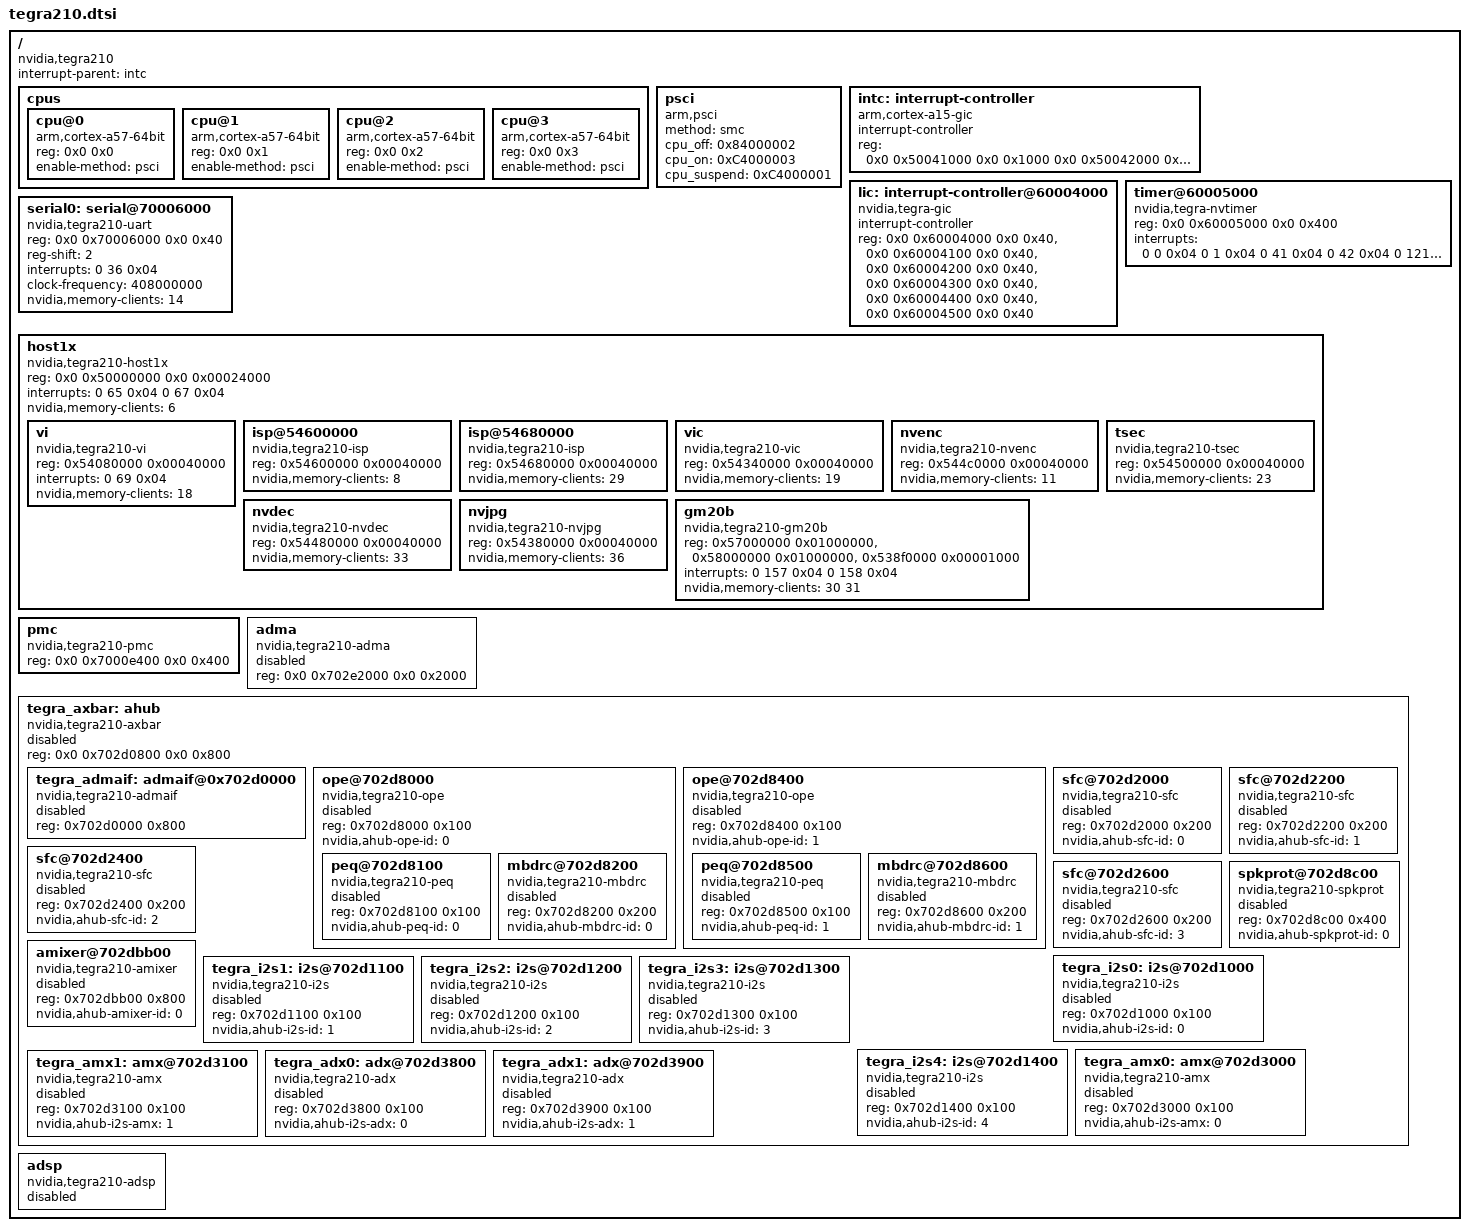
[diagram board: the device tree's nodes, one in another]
/*
 * arch/arm64/boot/dts/tegra210.dtsi
 *
 * Copyright (c) 2013-2014, NVIDIA CORPORATION.  All rights reserved.
 *
 * This program is free software; you can redistribute it and/or modify
 * it under the terms of the GNU General Public License as published by
 * the Free Software Foundation; version 2 of the License.
 *
 * This program is distributed in the hope that it will be useful, but WITHOUT
 * ANY WARRANTY; without even the implied warranty of MERCHANTABILITY or
 * FITNESS FOR A PARTICULAR PURPOSE.  See the GNU General Public License for
 * more details.
 *
 * You should have received a copy of the GNU General Public License along
 * with this program; if not, write to the Free Software Foundation, Inc.,
 * 51 Franklin Street, Fifth Floor, Boston, MA  02110-1301, USA.
 *
 */

/include/ "skeleton.dtsi"

/ {
	compatible = "nvidia,tegra210";
	interrupt-parent = <&intc>;
	#address-cells = <2>;
	#size-cells = <2>;

	cpus {
		#address-cells = <2>;
		#size-cells = <0>;

		cpu@0 {
			device_type = "cpu";
			compatible = "arm,cortex-a57-64bit", "arm,armv8";
			reg = <0x0 0x0>;
			enable-method = "psci";
		};

		cpu@1 {
			device_type = "cpu";
			compatible = "arm,cortex-a57-64bit", "arm,armv8";
			reg = <0x0 0x1>;
			enable-method = "psci";
		};

		cpu@2 {
			device_type = "cpu";
			compatible = "arm,cortex-a57-64bit", "arm,armv8";
			reg = <0x0 0x2>;
			enable-method = "psci";
		};

		cpu@3 {
			device_type = "cpu";
			compatible = "arm,cortex-a57-64bit", "arm,armv8";
			reg = <0x0 0x3>;
			enable-method = "psci";
		};
	};

	psci {
		compatible = "arm,psci";
		method = "smc";
		cpu_off = <0x84000002>;
		cpu_on = <0xC4000003>;
		cpu_suspend = <0xC4000001>;
	};

	intc: interrupt-controller {
		compatible = "arm,cortex-a15-gic";
		#interrupt-cells = <3>;
		interrupt-controller;
		reg = <0x0 0x50041000 0x0 0x1000
		       0x0 0x50042000 0x0 0x0100>;
	};

	lic: interrupt-controller@60004000 {
		compatible = "nvidia,tegra-gic";
		interrupt-controller;
		reg = <0x0 0x60004000 0x0 0x40>,
		      <0x0 0x60004100 0x0 0x40>,
		      <0x0 0x60004200 0x0 0x40>,
		      <0x0 0x60004300 0x0 0x40>,
		      <0x0 0x60004400 0x0 0x40>,
		      <0x0 0x60004500 0x0 0x40>;
	};

	timer@60005000 {
		compatible = "nvidia,tegra-nvtimer";
		reg = <0x0 0x60005000 0x0 0x400>;
		interrupts = <0 0 0x04
			      0 1 0x04
			      0 41 0x04
			      0 42 0x04
			      0 121 0x04
			      0 151 0x04
			      0 152 0x04
			      0 153 0x04
			      0 154 0x04
			      0 155 0x04
			      0 122 0x04>;
	};

	serial0: serial@70006000 {
		compatible = "nvidia,tegra210-uart", "nvidia,tegra30-uart", "nvidia,tegra20-uart";
		reg = <0x0 0x70006000 0x0 0x40>;
		reg-shift = <2>;
		interrupts = <0 36 0x04>;
		clock-frequency = <408000000>;
		nvidia,memory-clients = <14>;
	};

	host1x {
		compatible = "nvidia,tegra210-host1x", "simple-bus";
		reg = <0x0 0x50000000 0x0 0x00024000>;
		interrupts = <0 65 0x04   /* mpcore syncpt */
			      0 67 0x04>; /* mpcore general */
		nvidia,memory-clients = <6>;

		#address-cells = <1>;
		#size-cells = <1>;

		ranges;

		vi {
			compatible = "nvidia,tegra210-vi";
			reg = <0x54080000 0x00040000>;
			interrupts = <0 69 0x04>;
			nvidia,memory-clients = <18>;
		};

		isp@54600000 {
			compatible = "nvidia,tegra210-isp";
			reg = <0x54600000 0x00040000>;
			nvidia,memory-clients = <8>;
		};

		isp@54680000 {
			compatible = "nvidia,tegra210-isp";
			reg = <0x54680000 0x00040000>;
			nvidia,memory-clients = <29>;
		};

		vic {
			compatible = "nvidia,tegra210-vic";
			reg = <0x54340000 0x00040000>;
			nvidia,memory-clients = <19>;
		};

		nvenc {
			compatible = "nvidia,tegra210-nvenc";
			reg = <0x544c0000 0x00040000>;
			nvidia,memory-clients = <11>;
		};

		tsec {
			compatible = "nvidia,tegra210-tsec";
			reg = <0x54500000 0x00040000>;
			nvidia,memory-clients = <23>;
		};

		nvdec {
			compatible = "nvidia,tegra210-nvdec";
			reg = <0x54480000 0x00040000>;
			nvidia,memory-clients = <33>;
		};

		nvjpg {
			compatible = "nvidia,tegra210-nvjpg";
			reg = <0x54380000 0x00040000>;
			nvidia,memory-clients = <36>;
		};

		gm20b {
			compatible = "nvidia,tegra210-gm20b";
			reg = <0x57000000 0x01000000>,
			    <0x58000000 0x01000000>,
			    <0x538f0000 0x00001000>;
			    interrupts = <0 157 0x04
				    0 158 0x04>;
			nvidia,memory-clients = <30 31>;
		};
	};

	pmc {
		compatible = "nvidia,tegra210-pmc";
		reg = <0x0 0x7000e400 0x0 0x400>;
	};

	adma {
		compatible = "nvidia,tegra210-adma";
		reg = <0x0 0x702e2000 0x0 0x2000>;
		status = "disabled";
	};

	tegra_axbar: ahub {
		compatible = "nvidia,tegra210-axbar";
		reg = <0x0 0x702d0800 0x0 0x800>;
		status = "disabled";

		#address-cells = <1>;
		#size-cells = <1>;
		ranges = <0x702d0000 0x0 0x702d0000 0x00010000>;

		tegra_admaif: admaif@0x702d0000 {
			compatible = "nvidia,tegra210-admaif";
			reg = <0x702d0000 0x800>;
			status = "disabled";
		};

		ope@702d8000 {
			compatible = "nvidia,tegra210-ope";
			reg = <0x702d8000 0x100>;
			nvidia,ahub-ope-id = <0>;
			status = "disabled";

			#address-cells = <1>;
			#size-cells = <1>;
			ranges;

			peq@702d8100 {
				compatible = "nvidia,tegra210-peq";
				reg = <0x702d8100 0x100>;
				nvidia,ahub-peq-id = <0>;
				status = "disabled";
			};
			mbdrc@702d8200 {
				compatible = "nvidia,tegra210-mbdrc";
				reg = <0x702d8200 0x200>;
				nvidia,ahub-mbdrc-id = <0>;
				status = "disabled";
			};
		};

		ope@702d8400 {
			compatible = "nvidia,tegra210-ope";
			reg = <0x702d8400 0x100>;
			nvidia,ahub-ope-id = <1>;
			status = "disabled";

			#address-cells = <1>;
			#size-cells = <1>;
			ranges;

			peq@702d8500 {
				compatible = "nvidia,tegra210-peq";
				reg = <0x702d8500 0x100>;
				nvidia,ahub-peq-id = <1>;
				status = "disabled";
			};
			mbdrc@702d8600 {
				compatible = "nvidia,tegra210-mbdrc";
				reg = <0x702d8600 0x200>;
				nvidia,ahub-mbdrc-id = <1>;
				status = "disabled";
			};
		};

		sfc@702d2000 {
			compatible = "nvidia,tegra210-sfc";
			reg = <0x702d2000 0x200>;
			nvidia,ahub-sfc-id = <0>;
			status = "disabled";
		};

		sfc@702d2200 {
			compatible = "nvidia,tegra210-sfc";
			reg = <0x702d2200 0x200>;
			nvidia,ahub-sfc-id = <1>;
			status = "disabled";
		};

		sfc@702d2400 {
			compatible = "nvidia,tegra210-sfc";
			reg = <0x702d2400 0x200>;
			nvidia,ahub-sfc-id = <2>;
			status = "disabled";
		};

		sfc@702d2600 {
			compatible = "nvidia,tegra210-sfc";
			reg = <0x702d2600 0x200>;
			nvidia,ahub-sfc-id = <3>;
			status = "disabled";
		};

		spkprot@702d8c00 {
			compatible = "nvidia,tegra210-spkprot";
			reg = <0x702d8c00 0x400>;
			nvidia,ahub-spkprot-id = <0>;
			status = "disabled";
		};

		amixer@702dbb00 {
			compatible = "nvidia,tegra210-amixer";
			reg = <0x702dbb00 0x800>;
			nvidia,ahub-amixer-id = <0>;
			status = "disabled";
		};

		tegra_i2s0: i2s@702d1000 {
			compatible = "nvidia,tegra210-i2s";
			reg = <0x702d1000 0x100>;
			nvidia,ahub-i2s-id = <0>;
			status = "disabled";
		};

		tegra_i2s1: i2s@702d1100 {
			compatible = "nvidia,tegra210-i2s";
			reg = <0x702d1100 0x100>;
			nvidia,ahub-i2s-id = <1>;
			status = "disabled";
		};

		tegra_i2s2: i2s@702d1200 {
			compatible = "nvidia,tegra210-i2s";
			reg = <0x702d1200 0x100>;
			nvidia,ahub-i2s-id = <2>;
			status = "disabled";
		};

		tegra_i2s3: i2s@702d1300 {
			compatible = "nvidia,tegra210-i2s";
			reg = <0x702d1300 0x100>;
			nvidia,ahub-i2s-id = <3>;
			status = "disabled";
		};

		tegra_i2s4: i2s@702d1400 {
			compatible = "nvidia,tegra210-i2s";
			reg = <0x702d1400 0x100>;
			nvidia,ahub-i2s-id = <4>;
			status = "disabled";
		};

		tegra_amx0: amx@702d3000 {
			compatible = "nvidia,tegra210-amx";
			reg = <0x702d3000 0x100>;
			nvidia,ahub-i2s-amx = <0>;
			status = "disabled";
		};

		tegra_amx1: amx@702d3100 {
			compatible = "nvidia,tegra210-amx";
			reg = <0x702d3100 0x100>;
			nvidia,ahub-i2s-amx = <1>;
			status = "disabled";
		};

		tegra_adx0: adx@702d3800 {
			compatible = "nvidia,tegra210-adx";
			reg = <0x702d3800 0x100>;
			nvidia,ahub-i2s-adx = <0>;
			status = "disabled";
		};

		tegra_adx1: adx@702d3900 {
			compatible = "nvidia,tegra210-adx";
			reg = <0x702d3900 0x100>;
			nvidia,ahub-i2s-adx = <1>;
			status = "disabled";
		};
	};

	adsp {
	     compatible = "nvidia,tegra210-adsp";
	     status = "disabled";
	};
};
